# S32R372 register map
Vendor: Freescale Semiconductor, Inc.; Series: Qorivva; File version: 1.6
Registers are 32-bit, read-write, reset 0x0 unless marked. A register's access mark holds for its fields unless they carry their own. Offsets are from the block's base; [hi:lo] are bit positions; {n}, {i} and the like mark numbered series; 'fields as' and 'values as' point back to an identical list.

## SPT — Signal Processing Toolbox
Base 0xFFD10000; register names take the prefix SPT_
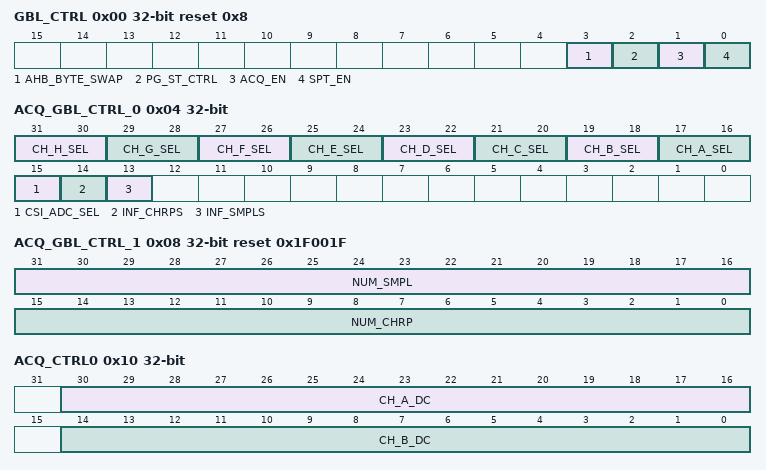
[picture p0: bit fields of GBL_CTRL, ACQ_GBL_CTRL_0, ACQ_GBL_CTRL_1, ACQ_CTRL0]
0x00 GBL_CTRL reset 0x8 — SPT Global Control Register
  [3] AHB_BYTE_SWAP — Bit to control data byte swapping on the AHB interface.
  [2] PG_ST_CTRL — Program start control
  [1] ACQ_EN — Acquisition Enable.
    0=Acquisition module is disabled. Acquisition and SDMA registers can now be programmed.; 1=Acquisition module is enabled. ADC samples can now be collected by acquisition block which are processed and transferred to System RAM by SDMA via AHB bus.
  [0] SPT_EN — SPT Enable
    0=SPT is disabled; 1=SPT is enabled
0x04 ACQ_GBL_CTRL_0 — Acquisition Global Control Register
  [31:30] CH_H_SEL — Channel H Select
    0=Channel Disabled; 1=Enable Channel H
  [29:28] CH_G_SEL — Channel G Select
    0=Channel Disabled; 1=Enable Channel G
  [27:26] CH_F_SEL — Channel F Select
    0=Channel Disabled; 1=Enable Channel F
  [25:24] CH_E_SEL — Channel E Select
    0=Channel Disabled; 1=Enable Channel E
  [23:22] CH_D_SEL — Channel D Select
    0=Channel Disabled; 1=Enable Channel D
  [21:20] CH_C_SEL — Channel C Select
    0=Channel Disabled; 1=Enable Channel C
  [19:18] CH_B_SEL — Channel B Select
    0=Channel Disabled; 1=Enable Channel B
  [17:16] CH_A_SEL — Channel A Select
    0=Channel Disabled; 1=Enable Channel A
  [15] CSI_ADC_SEL — CSI Select
    0=Acquisition source is disabled; 1=acquisition source is MIPICSI2 data
  [14] INF_CHRPS — Infinite Chirps in a Frame
    0=The number of chirps within a frame is limited and is programmable via ACQ_GBL_CTRL_1[NUM_CHRP] field; 1=The number of chirps within a frame is unlimited
  [13] INF_SMPLS — Infinite Samples in a Chirp
    0=The number of samples within a chirp is limited and is programmable via ACQ_GBL_CTRL_1[NUM_SMPL] field; 1=The number of samples within a chirp is unlimited
0x08 ACQ_GBL_CTRL_1 reset 0x1F001F — Acquisition Global Control Register 1
  [31:16] NUM_SMPL — Number of Samples in a Chirp
  [15:0] NUM_CHRP — Number of chirps in a frame
0x10 ACQ_CTRL0 — Acquisition Control 0 Register
  [30:16] CH_A_DC — Channel A Offset Compensation value
  [14:0] CH_B_DC — Channel B Offset Compensation value
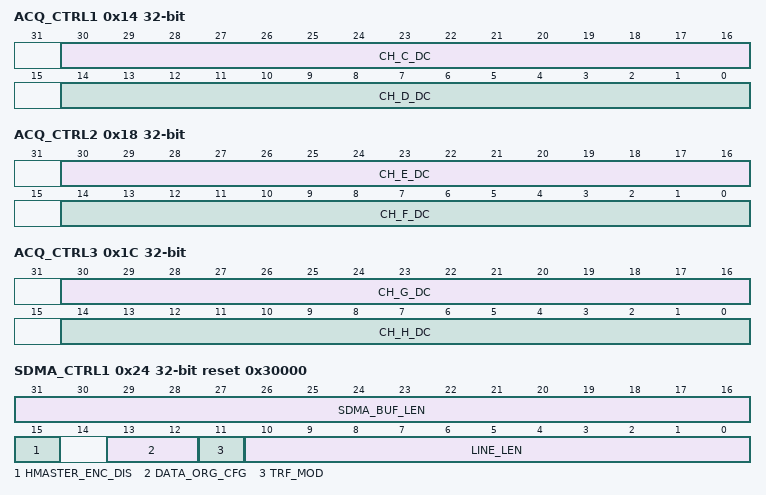
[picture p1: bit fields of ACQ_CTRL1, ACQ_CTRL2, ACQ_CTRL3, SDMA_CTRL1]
0x14 ACQ_CTRL1 — Acquisition Control 1 Register
  [30:16] CH_C_DC — Channel C Offset Compensation value
  [14:0] CH_D_DC — Channel D Offset Compensation value
0x18 ACQ_CTRL2 — Acquisition Control 2 Register
  [30:16] CH_E_DC — Channel E Offset Compensation value
  [14:0] CH_F_DC — Channel F Offset Compensation value
0x1C ACQ_CTRL3 — Acquisition Control 3 Register
  [30:16] CH_G_DC — Channel G Offset Compensation value
  [14:0] CH_H_DC — Channel H Offset Compensation value
0x20 SDMA_CTRL0 — SDMA Control 0 Register
  [31:3] SDMA_START_ADDR — SDMA Start Address
0x24 SDMA_CTRL1 reset 0x30000 — SDMA Control 1 Register
  [31:16] SDMA_BUF_LEN — SDMA Buffer Length
  [15] HMASTER_ENC_DIS — AHB Master ID generation disable
    0=Duplicate AHB Master ID generated. In this case the Duplicate AHB Master ID at the top shows a value different from the Crossbar Master ID; 1=Duplicate AHB Master ID not generated. In this case the Duplicate AHB Master ID at the top shows the same value as the Crossbar Master ID
  [13:12] DATA_ORG_CFG — Data Organization Configuration
    0=Interleaved Mode; 1=Tile 4 Mode; 2=Tile 8 Mode
  [11] TRF_MOD — Transfer Mode
    0=Selects Linear (1D) Mode; 1=Selects Orthogonal (2D) Mode
  [10:0] LINE_LEN — Line Length
0x44 ACQ_STATUS_A0 ro — Acquisition Status Register A0
  [31:0] CH_A_SUM — Channel A Sum
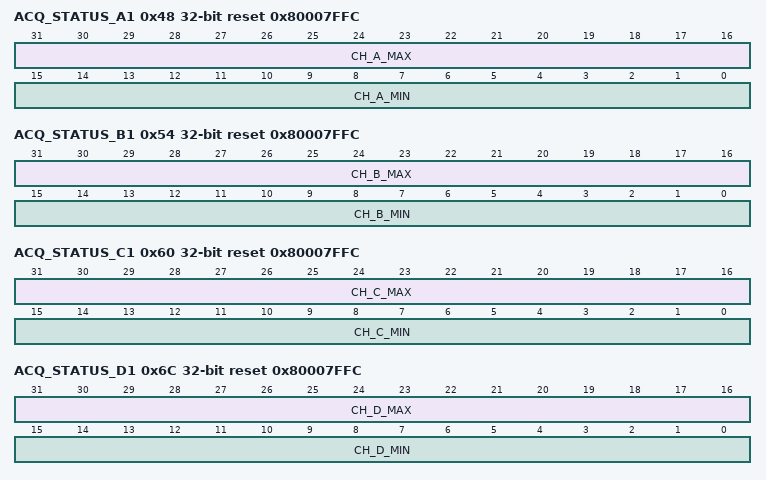
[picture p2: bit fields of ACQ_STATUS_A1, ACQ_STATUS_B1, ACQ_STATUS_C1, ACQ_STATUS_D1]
0x48 ACQ_STATUS_A1 ro reset 0x80007FFC — Acquisition Status Register A1
  [31:16] CH_A_MAX — Channel A Maximum
  [15:0] CH_A_MIN — Channel A Minimum
0x4C ACQ_STATUS_A2 ro — Acquisition Status Register A2
  [15:0] CH_A_BT — Channel A Bit Toggle
    0=The corresponding bit did not toggle; 1=The corresponding bit has toggled
0x50 ACQ_STATUS_B0 ro — Acquisition Status Register B0
  [31:0] CH_B_SUM — Channel B Sum
0x54 ACQ_STATUS_B1 ro reset 0x80007FFC — Acquisition Status Register B1
  [31:16] CH_B_MAX — Channel B Maximum
  [15:0] CH_B_MIN — Channel B Minimum
0x58 ACQ_STATUS_B2 ro — Acquisition Status Register B2
  [15:0] CH_B_BT — Channel B Bit Toggle
    values as ACQ_STATUS_A2.CH_A_BT
0x5C ACQ_STATUS_C0 ro — Acquisition Status Register C0
  [31:0] CH_C_SUM — Channel C Sum
0x60 ACQ_STATUS_C1 ro reset 0x80007FFC — Acquisition Status Register C1
  [31:16] CH_C_MAX — Channel C Maximum
  [15:0] CH_C_MIN — Channel C Minimum
0x64 ACQ_STATUS_C2 ro — Acquisition Status Register C2
  [15:0] CH_C_BT — Channel C Bit Toggle
    values as ACQ_STATUS_A2.CH_A_BT
0x68 ACQ_STATUS_D0 ro — Acquisition Status Register D0
  [31:0] CH_D_SUM — Channel D Sum
0x6C ACQ_STATUS_D1 ro reset 0x80007FFC — Acquisition Status Register D1
  [31:16] CH_D_MAX — Channel D Maximum
  [15:0] CH_D_MIN — Channel D Minimum
0x70 ACQ_STATUS_D2 ro — Acquisition Status Register D2
  [15:0] CH_D_BT — Channel D Bit Toggle
    values as ACQ_STATUS_A2.CH_A_BT
0x74 ACQ_STATUS_E0 ro — Acquisition Status Register E0
  [31:0] CH_E_SUM — Channel E Sum
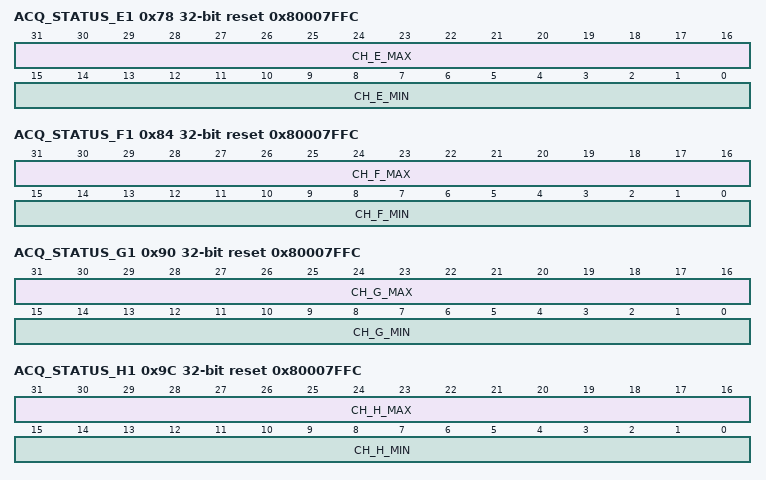
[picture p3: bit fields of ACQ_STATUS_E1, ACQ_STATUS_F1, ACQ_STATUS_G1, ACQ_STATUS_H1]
0x78 ACQ_STATUS_E1 ro reset 0x80007FFC — Acquisition Status Register E1
  [31:16] CH_E_MAX — Channel E Maximum
  [15:0] CH_E_MIN — Channel E Minimum
0x7C ACQ_STATUS_E2 ro — Acquisition Status Register E2
  [15:0] CH_E_BT — Channel E Bit Toggle
    values as ACQ_STATUS_A2.CH_A_BT
0x80 ACQ_STATUS_F0 ro — Acquisition Status Register F0
  [31:0] CH_F_SUM — Channel F Sum
0x84 ACQ_STATUS_F1 ro reset 0x80007FFC — Acquisition Status Register F1
  [31:16] CH_F_MAX — Channel F Maximum
  [15:0] CH_F_MIN — Channel F Minimum
0x88 ACQ_STATUS_F2 ro — Acquisition Status Register F2
  [15:0] CH_F_BT — Channel F Bit Toggle
    values as ACQ_STATUS_A2.CH_A_BT
0x8C ACQ_STATUS_G0 ro — Acquisition Status Register G0
  [31:0] CH_G_SUM — Channel G Sum
0x90 ACQ_STATUS_G1 ro reset 0x80007FFC — Acquisition Status Register G1
  [31:16] CH_G_MAX — Channel G Maximum
  [15:0] CH_G_MIN — Channel G Minimum
0x94 ACQ_STATUS_G2 ro — Acquisition Status Register G2
  [15:0] CH_G_BT — Channel G Bit Toggle
    values as ACQ_STATUS_A2.CH_A_BT
0x98 ACQ_STATUS_H0 ro — Acquisition Status Register H0
  [31:0] CH_H_SUM — Channel H Sum
0x9C ACQ_STATUS_H1 ro reset 0x80007FFC — Acquisition Status Register H1
  [31:16] CH_H_MAX — Channel H Maximum
  [15:0] CH_H_MIN — Channel H Minimum
0xA0 ACQ_STATUS_H2 ro — Acquisition Status Register H2
  [15:0] CH_H_BT — Channel H Bit Toggle
    values as ACQ_STATUS_A2.CH_A_BT
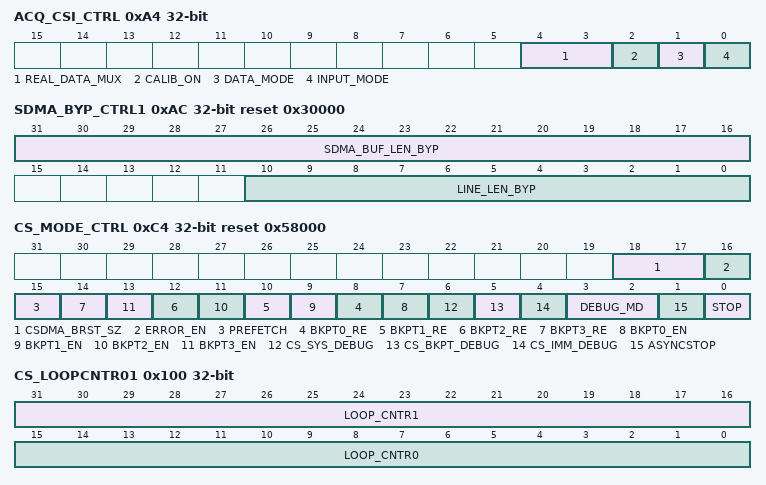
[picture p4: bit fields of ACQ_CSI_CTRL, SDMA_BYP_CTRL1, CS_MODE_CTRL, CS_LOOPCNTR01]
0xA4 ACQ_CSI_CTRL — Acquisition MIPICSI2 control register
  [4:3] REAL_DATA_MUX — Configures the sequence of data when channel 5 is on
    0=Channel A-D at 10MSPS and channel E at 10MSPS. RAW14 does not support this mode.; 1=Channel A-D at 5MSPS and channel E at 10MSPS; 2=Channel A-D at 2.5MSPS and channel E at 10MSPS; 3=Channel A-D at 6.667MSPS and channel E at 13.33MSPS
  [2] CALIB_ON — Enables the fifth channel
    0=calibration channel off; 1=calibration channel on
  [1] DATA_MODE — Defines the type of data.
    0=Input data is Real only; 1=Input data is complex (Real and Imaginary)
  [0] INPUT_MODE — Input Mode select
    0=Input data is in Tile4 format. Each channel receives 4 consecutive valid data.; 1=Input data in Interleaved format. Each channel receives 1 valid data at a time.
0xA8 SDMA_BYP_CTRL0 — Bypass SDMA Control 0
  [31:3] SDMA_START_ADDR_BYP — Bypass SDMA Start Address
0xAC SDMA_BYP_CTRL1 reset 0x30000 — Bypass SDMA Control 1 Register
  [31:16] SDMA_BUF_LEN_BYP — Bypass SDMA Buffer Length
  [10:0] LINE_LEN_BYP — Line Length Bypass
0xB0 ACQ_BYP_CTRL reset 0x1F0000 — Acquisition Bypass Control Register
  [31:16] NUM_SMPL_BYP — Number of Samples in a Chirp
0xC0 CS_PG_ST_ADDR — Program Start Addr Register
  [31:0] PG_ST_ADDR — Program start address
0xC4 CS_MODE_CTRL reset 0x58000 — Mode Control Register
  [18:17] CSDMA_BRST_SZ — Command Sequencer DMA Burst Size
    0=The burst size is INCR4; 1=The burst size is INCR8; 0b1x=The burst size is INCR16
  [16] ERROR_EN — Error Enable
  [15] PREFETCH — Early Pre-fetch Enable
    0=Early pre-fetch option disabled; 1=Early pre-fetch option enabled
  [2n+8] BKPT{n}_RE (n=0..3) — Breakpoint {n} remains enabled
  [2n+7] BKPT{n}_EN (n=0..3) — Breakpoint {n} enabled
  [6] CS_SYS_DEBUG — System debug enable
  [5] CS_BKPT_DEBUG — Breakpoint debug enable
  [4] CS_IMM_DEBUG — IMM DEBUG enable
  [3:2] DEBUG_MD — DEBUG MODE control
  [1] ASYNCSTOP wo — Asynchronous STOP bit
  [0] STOP wo — STOP bit
0xC8 CS_WD_COUNT ro — Watchdog Counter Register
  [23:0] WD_COUNT — Watchdog timer count
{0xCC+4i} CS_BKPT{i}_ADDR (i=0..3) — Breakpoint{i} Addr Register
  [31:0] BKPT{i} — Breakpoint {i} address
0xDC CS_JAM_INST0 — Jamming Instruction0 Register
  [31:0] JAM_INST_127_96 — Jamming instruction bits 127:96
0xE0 CS_JAM_INST1 — Jamming Instruction1 Register
  [31:0] JAM_INST_95_64 — Jamming instruction bits 95:64
0xE4 CS_JAM_INST2 — Jamming Instruction2 Register
  [31:0] JAM_INST_63_32 — Jamming instruction bits 63:32
0xE8 CS_JAM_INST3 — Jamming Instruction3 Register
  [31:0] JAM_INST_31_0 — Jamming instruction bits 31:0
0xEC CS_CURR_INST_ADDR ro — Current Instruction Addr Register
  [31:0] CURRENT_INST_ADDR — Current instruction pointer
0xF0 CS_CURR_INST0 ro — Current Instruction0 Register
  [31:0] CURR_INST_127_96 — Current instruction bits 127:96
0xF4 CS_CURR_INST1 ro — Current Instruction1 Register
  [31:0] CURR_INST_95_64 — Current instruction bits 95:64
0xF8 CS_CURR_INST2 ro — Current Instruction2 Register
  [31:0] CURR_INST_63_32 — Current instruction bits 63:32
0xFC CS_CURR_INST3 ro — Current Instruction3 Register
  [31:0] CURR_INST_31_0 — Current instruction bits 31:0
0x100 CS_LOOPCNTR01 ro — Loop Counter 0 and 1 Register
  [31:16] LOOP_CNTR1 — Loop count of counter 1
  [15:0] LOOP_CNTR0 — Loop count of counter 0
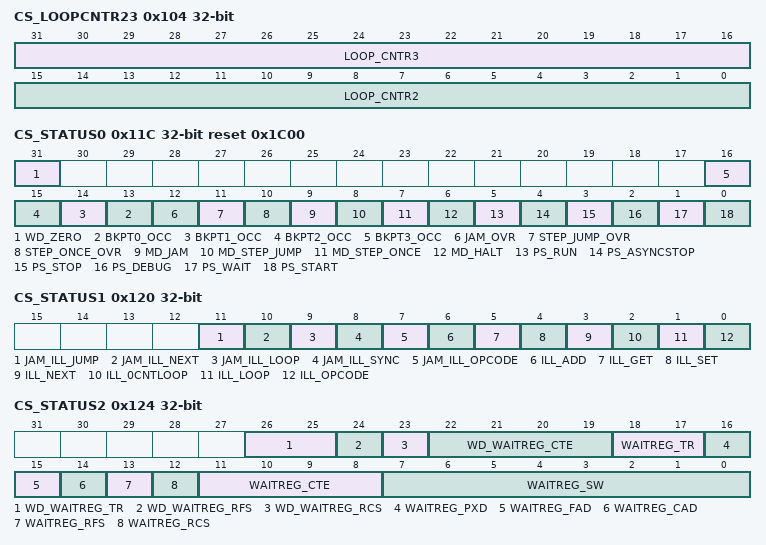
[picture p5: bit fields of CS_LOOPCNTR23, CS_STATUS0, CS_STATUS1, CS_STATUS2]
0x104 CS_LOOPCNTR23 ro — Loop Counter 2 and 3 Register
  [31:16] LOOP_CNTR3 — Loop count of counter 3
  [15:0] LOOP_CNTR2 — Loop count of counter 2
0x108 CS_ERR_INST_ADDR ro — Error Instruction Addr Register
  [31:0] ERROR_INST_ADDR — Error instruction pointer
0x10C CS_ERR_INST0 ro — Error Instruction 0 Register
  [31:0] ERR_INST_127_96 — Error instruction bits 127:96
0x110 CS_ERR_INST1 ro — Error Instruction 1 Register
  [31:0] ERR_INST_95_64 — Error instruction bits 95:64
0x114 CS_ERR_INST2 ro — Error Instruction 2 Register
  [31:0] ERR_INST_63_32 — Error instruction bits 63:32
0x118 CS_ERR_INST3 ro — Error Instruction 3 Register
  [31:0] ERR_INST_31_0 — Error instruction bits 31:0
0x11C CS_STATUS0 reset 0x1C00 — General Status 0 Register
  [31] WD_ZERO — Watchdog timer reached zero
  [n+13] BKPT{n}_OCC (n=0..3) — 'Breakpoint {n} hit' indication
  [12] JAM_OVR — Jamming mode instruction completion indication
  [11] STEP_JUMP_OVR — STEP JUMP mode break indication
  [10] STEP_ONCE_OVR — STEP ONCE mode instruction completion indication
  [9] MD_JAM — INSTRUCTION JAMMING mode indicator
  [8] MD_STEP_JUMP — STEP JUMP mode indicator
  [7] MD_STEP_ONCE — STEP ONCE mode indicator
  [6] MD_HALT — HALT MODE indicator
  [5] PS_RUN — RUN state indicator
  [4] PS_ASYNCSTOP — ASYNCSTOP state indicator
  [3] PS_STOP — STOP state indicator
  [2] PS_DEBUG — DEBUG state indicator
  [1] PS_WAIT — WAIT state indicator
  [0] PS_START — START state indicator
0x120 CS_STATUS1 — General Status 1 Register
  [11] JAM_ILL_JUMP — Illegal JUMP in jamming mode
  [10] JAM_ILL_NEXT — Illegal NEXT in jamming mode
  [9] JAM_ILL_LOOP — Illegal LOOP in jamming mode
  [8] JAM_ILL_SYNC — Illegal SYNC in jamming mode
  [7] JAM_ILL_OPCODE — Illegal opcode in jamming mode
  [6] ILL_ADD — Illegal ADD
  [5] ILL_GET — Illegal GET
  [4] ILL_SET — Illegal SET
  [3] ILL_NEXT — Illegal NEXT
  [2] ILL_0CNTLOOP — Illegal loop count error
  [1] ILL_LOOP — illegal LOOP
  [0] ILL_OPCODE — Illegal opcode
0x124 CS_STATUS2 ro — General Status2 Register
  [26:25] WD_WAITREG_TR — Event trigger type for WATCHDOG timer
  [24] WD_WAITREG_RFS — Watchdog waits for cte_rfs or csi_vsync signal
  [23] WD_WAITREG_RCS — Watchdog waits for cte_rcs or csi_hsync signal
  [22:19] WD_WAITREG_CTE — Watchdog waits for CTE
  [18:17] WAITREG_TR — Event trigger type
  [16] WAITREG_PXD — WAIT status for 'pdma transfer done' signal
  [15] WAITREG_FAD — WAIT status for 'frame acquisition done' signal
  [14] WAITREG_CAD — WAIT status for 'chirp acquisition done' signal
  [13] WAITREG_RFS — WAIT status for cte_rfs
  [12] WAITREG_RCS — WAIT status for cte_rcs
  [11:8] WAITREG_CTE — WAIT status for CTE event
  [7:0] WAITREG_SW — WAIT status for SW-enforced event
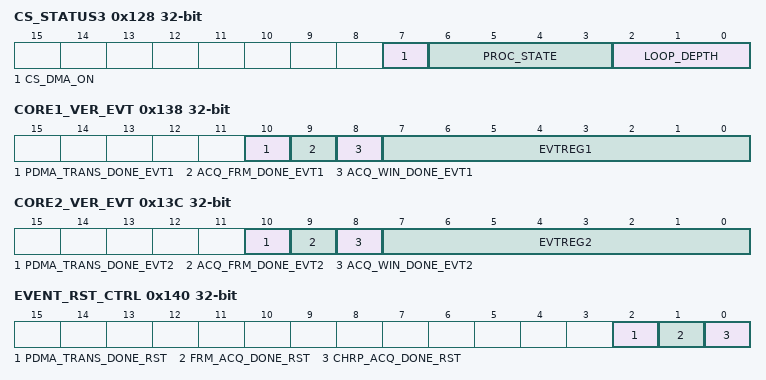
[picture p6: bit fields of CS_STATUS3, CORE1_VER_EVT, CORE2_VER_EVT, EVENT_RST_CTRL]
0x128 CS_STATUS3 ro — General Status 3 Register
  [7] CS_DMA_ON — Command sequencer DMA ON
  [6:3] PROC_STATE — Processing state
  [2:0] LOOP_DEPTH
0x12C CS_EVTREG1 — EVT1 Status Register
  [7:0] EVTREG1 — EVT1 register
0x130 CS_EVTREG2 — EVT2 Status Register
  [7:0] EVTREG2 — EVT2 register
0x134 CS_SW_EVTREG — SW Event Trigger Register
  [7:0] SW_EVTREG — SW event trigger
0x138 CORE1_VER_EVT — Core 1 Version Register Events
  [10] PDMA_TRANS_DONE_EVT1 — Event for PDMA transfer done for CPU core 1
  [9] ACQ_FRM_DONE_EVT1 — Event for acquisition frame done for CPU core 1
  [8] ACQ_WIN_DONE_EVT1 — Event for acquisition window finished for CPU core 1
  [7:0] EVTREG1 — EVT1 register
0x13C CORE2_VER_EVT — Core 2 Version Register Events
  [10] PDMA_TRANS_DONE_EVT2 — Event for PDMA transfer done for CPU core 2
  [9] ACQ_FRM_DONE_EVT2 — Event for acquisition frame done for CPU core 2
  [8] ACQ_WIN_DONE_EVT2 — Event for acquisition window finished for CPU core 2
  [7:0] EVTREG2 — EVT2 register
0x140 EVENT_RST_CTRL — SPT Event Reset Control Register
  [2] PDMA_TRANS_DONE_RST wo — When a 1 is written to this bit it causes the registered PDMA Transfer Done event inside the WAIT module to be reset
  [1] FRM_ACQ_DONE_RST wo — When a 1 is written to this bit it causes the registered Frame Acquisition Done event inside the WAIT module to be reset
  [0] CHRP_ACQ_DONE_RST wo — When a 1 is written to this bit it causes the registered Chirp Acquisition Done event inside the WAIT module to be reset
0x180 PDMA_LFSR_LOAD_VAL_HIGH — LFSR Load High Value
  [31:0] PDMA_LFSR_LOAD_VAL_HIGH — LFSR High value [63:32] for compression
0x184 PDMA_LFSR_LOAD_VAL_LOW — LFSR Load Low Value
  [31:0] PDMA_LFSR_LOAD_VAL_LOW — LFSR Low Value [31:0] for compression
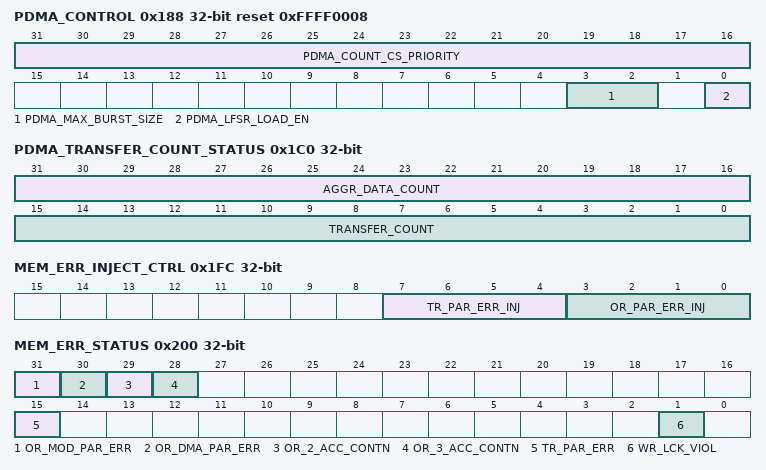
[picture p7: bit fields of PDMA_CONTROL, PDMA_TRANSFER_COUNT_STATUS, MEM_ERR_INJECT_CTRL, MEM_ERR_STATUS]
0x188 PDMA_CONTROL reset 0xFFFF0008
  [31:16] PDMA_COUNT_CS_PRIORITY — PDMA Count register for Command sequencer to get priority
  [3:2] PDMA_MAX_BURST_SIZE — Maximum AHB burst size
  [0] PDMA_LFSR_LOAD_EN — LFSR load enable bit
0x1C0 PDMA_TRANSFER_COUNT_STATUS ro
  [31:16] AGGR_DATA_COUNT — Aggregation Data Count
  [15:0] TRANSFER_COUNT — Number of words transferred via PDMA
0x1C4 PDMA_FMTB_EXP_ADDR_STATUS ro — PDMA formatB Exponent Address status Register
  [31:0] EXPN_ADDR — Exponent Address
0x1FC MEM_ERR_INJECT_CTRL — Memory Error Injection Register
  [7:4] TR_PAR_ERR_INJ — Twiddle RAM parity error Injection
  [3:0] OR_PAR_ERR_INJ — Operand RAM parity error Injection
0x200 MEM_ERR_STATUS — Memory Error Status Register
  [31] OR_MOD_PAR_ERR — Operand RAM module parity error
  [30] OR_DMA_PAR_ERR — Operand RAM DMA parity error
  [29] OR_2_ACC_CONTN — Operand RAM two access contention
  [28] OR_3_ACC_CONTN — Operand RAM three access contention
  [15] TR_PAR_ERR — Twiddle RAM parity error
  [1] WR_LCK_VIOL — Work register lock violation
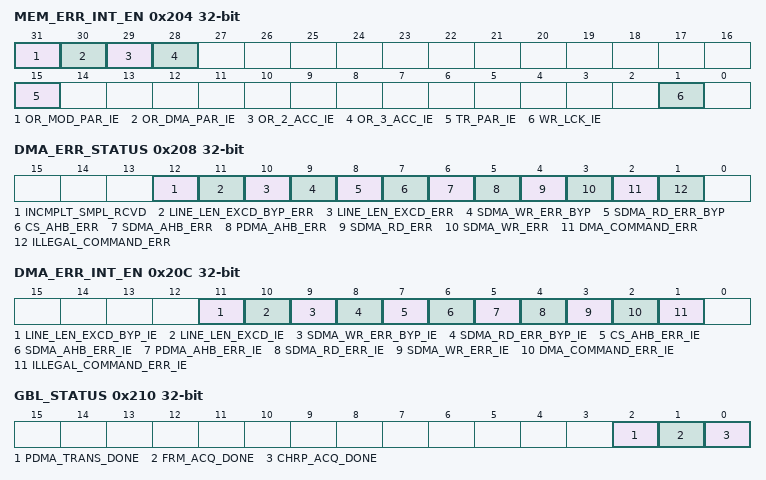
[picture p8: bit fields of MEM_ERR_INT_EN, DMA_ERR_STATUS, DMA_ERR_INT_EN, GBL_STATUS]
0x204 MEM_ERR_INT_EN — Memory Interrupt Enable register
  [31] OR_MOD_PAR_IE — Operand RAM module parity interrupt enable
  [30] OR_DMA_PAR_IE — Operand RAM DMA parity interrupt enable
  [29] OR_2_ACC_IE — Operand RAM two access contention interrupt enable
  [28] OR_3_ACC_IE — Operand RAM three access contention interrupt enable
  [15] TR_PAR_IE — Twiddle RAM parity error interrupt enable
  [1] WR_LCK_IE — Work register lock interrupt enable
0x208 DMA_ERR_STATUS — DMA Error Status Register
  [12] INCMPLT_SMPL_RCVD — Incomplete sample received
  [11] LINE_LEN_EXCD_BYP_ERR — Bypass SDMA line length exceeded
  [10] LINE_LEN_EXCD_ERR — Line Length Exceeded
  [9] SDMA_WR_ERR_BYP — Bypass SDMA write error
  [8] SDMA_RD_ERR_BYP — Bypass SDMA read error
  [7] CS_AHB_ERR — Command Sequencer AHB error Response
  [6] SDMA_AHB_ERR — SDMA AHB Error Response
  [5] PDMA_AHB_ERR — PDMA AHB Error
  [4] SDMA_RD_ERR — SDMA Read Error
  [3] SDMA_WR_ERR — SDMA Write Error
  [2] DMA_COMMAND_ERR — Generated if the transfer size is more than the maximum value possible
  [1] ILLEGAL_COMMAND_ERR — Generated if proprietary functionality is tried being used by user.
0x20C DMA_ERR_INT_EN — Interrupt Enable for DMA_ERROR_STATUS
  [11] LINE_LEN_EXCD_BYP_IE — Bypass SDMA line length exceeded interrupt
    0=Interrupt generation disabled; 1=Interrupt generation enabled
  [10] LINE_LEN_EXCD_IE — Line length exceeded interrupt
    values as LINE_LEN_EXCD_BYP_IE
  [9] SDMA_WR_ERR_BYP_IE — Bypass SDMA write error interrupt
    values as LINE_LEN_EXCD_BYP_IE
  [8] SDMA_RD_ERR_BYP_IE — Bypass SDMA read error interrupt
    values as LINE_LEN_EXCD_BYP_IE
  [7] CS_AHB_ERR_IE — Command Sequencer AHB Interrupt Enable
  [6] SDMA_AHB_ERR_IE — SDMA AHB Error Interrupt Enable
  [5] PDMA_AHB_ERR_IE — Interrupt Enable for PDMA AHB Error
  [4] SDMA_RD_ERR_IE — SDMA Read Error Interrupt Enable
    values as LINE_LEN_EXCD_BYP_IE
  [3] SDMA_WR_ERR_IE — SDMA Write Error Interrupt Enable
    values as LINE_LEN_EXCD_BYP_IE
  [2] DMA_COMMAND_ERR_IE — Generated if the transfer size is more than the maximum value possible
  [1] ILLEGAL_COMMAND_ERR_IE — Generated if proprietary functionality is tried being used by user.
0x210 GBL_STATUS — Global Status Register
  [2] PDMA_TRANS_DONE — PDMA transfer done
  [1] FRM_ACQ_DONE — Frame Acquisition Done
    0=Frame Acquisition is not done; 1=Frame Acquisition is done
  [0] CHRP_ACQ_DONE — Chirp Acquisition Done
    0=Chirp Acquisition is not done; 1=Chirp acquisition is done
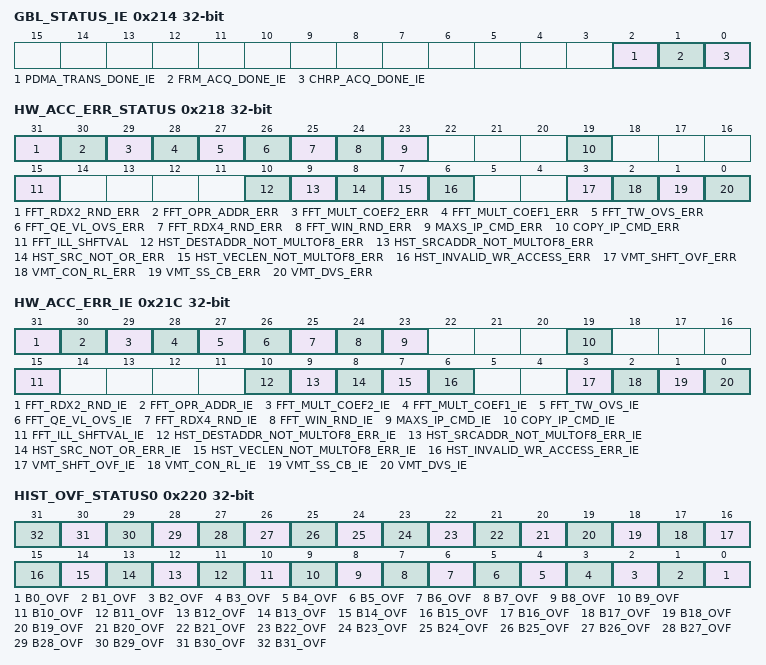
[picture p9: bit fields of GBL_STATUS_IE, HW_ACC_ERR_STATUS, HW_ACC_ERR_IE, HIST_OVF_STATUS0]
0x214 GBL_STATUS_IE — Global Status Interrupt Enable Register
  [2] PDMA_TRANS_DONE_IE — PDMA transfer done interrupt enable
  [1] FRM_ACQ_DONE_IE — Frame Acquisition Done Interrupt Enable
    0=Interrupt Disabled; 1=Interrupt Enabled
  [0] CHRP_ACQ_DONE_IE — Chirp Acquisition Done Interrupt Enable
    0=Interrupt Disabled; 1=Interrupt Enabled
0x218 HW_ACC_ERR_STATUS — Hardware Accelerator Error Status Register
  [31] FFT_RDX2_RND_ERR — FFT Radix2 Round Error
  [30] FFT_OPR_ADDR_ERR — Operand Address Error
  [29] FFT_MULT_COEF2_ERR — FFT MULT Co-efficient 2 Error
  [28] FFT_MULT_COEF1_ERR — FFT MULT Co-efficient 1 Error
  [27] FFT_TW_OVS_ERR — FFT Twiddle Oversampling Error
  [26] FFT_QE_VL_OVS_ERR — Quadrature Extension Vector Length Oversampling Error
  [25] FFT_RDX4_RND_ERR — FFT Radix4 Round Error
  [24] FFT_WIN_RND_ERR — FFT Window Round Error
  [23] MAXS_IP_CMD_ERR — MAXS input command error
    0=No command error; 1=Asserted when any of the following errors are encountered in the incoming instruction. Refer Error scenarios
  [19] COPY_IP_CMD_ERR — COPY input command error
    0=No command error; 1=Asserted when any of the following command errors are encountered: 1.In in_dattyp = CMPLX and preproc = 0 (no preproc) 2.If in_dattyp != CMPLX and preproc = 2 (MAG) 3.If (src_add[15:14] = WREG_ADD or dest_add[15:14] = WREG_ADD) 4.In_dattyp == 11b (RESERVED) 5.Preproc == 11b (RESERVED) 6.Cp_type >= 1100b 7.Cp_type == CP_TRNSPOSE and vec_sz[5:0] != 0 8.Vec_sz[3:0] != 0 9.Cp_type == CP_SHFT AND dest_add[3:0] == 0 // copy shift with 0 shift not allowed
  [15] FFT_ILL_SHFTVAL — FFT Illegal Shift Value error
  [10] HST_DESTADDR_NOT_MULTOF8_ERR — Destination address not multiple of 8 error
  [9] HST_SRCADDR_NOT_MULTOF8_ERR — Source address not multiple of 8 error
  [8] HST_SRC_NOT_OR_ERR — Source not Operand RAM error
  [7] HST_VECLEN_NOT_MULTOF8_ERR — Vector length not multiple of 8 error
  [6] HST_INVALID_WR_ACCESS_ERR — HIST work register access error
  [3] VMT_SHFT_OVF_ERR — VMT Shift Overflow Error
    0=No saturation condition hit; 1=Saturation condition is hit
  [2] VMT_CON_RL_ERR — VMT Conjugate with Real Type Error
    0=No Error; 1=Error condition is hit
  [1] VMT_SS_CB_ERR — VMT Sum Scale with Conjugate/Bypass Error
    0=No Error; 1=Error condition is hit
  [0] VMT_DVS_ERR — VMT Dual vector sum error
    0=No Error; 1=Error condition is hit
0x21C HW_ACC_ERR_IE — Hardware Accelerator Error Interrupt Enable Register
  [31] FFT_RDX2_RND_IE — FFT Radix2 Round Error Interrupt Enable
  [30] FFT_OPR_ADDR_IE — Operand Address Interrupt Enable
    0=Interrupt Disabled; 1=Interrupt Enabled
  [29] FFT_MULT_COEF2_IE — FFT MULT Co-efficient 2 Interrupt Enable
    0=Interrupt Disabled; 1=Interrupt Enabled
  [28] FFT_MULT_COEF1_IE — FFT MULT Co-efficient 1 Interrupt Enable
    0=Interrupt Disabled; 1=Interrupt Enabled
  [27] FFT_TW_OVS_IE — FFT Twiddle Oversampling Interrupt Enable
    0=Interrupt Disabled; 1=Interrupt Enabled
  [26] FFT_QE_VL_OVS_IE — Quadrature Extension Vector Length Oversampling Interrupt Enable
    0=Interrupt Disabled; 1=Interrupt Enabled
  [25] FFT_RDX4_RND_IE — FFT Radix4 Round Error Interrupt Enable
  [24] FFT_WIN_RND_IE — FFT Window Round Interrupt Enable
    0=Interrupt Disabled; 1=Interrupt Enabled
  [23] MAXS_IP_CMD_IE — MAXS input command interrupt enable
  [19] COPY_IP_CMD_IE — COPY input command interrupt enable
  [15] FFT_ILL_SHFTVAL_IE — FFT Illegal Shift Value Error
  [10] HST_DESTADDR_NOT_MULTOF8_ERR_IE — Destination address not multiple of 8 error interrupt enable
  [9] HST_SRCADDR_NOT_MULTOF8_ERR_IE — Source address not multiple of 8 error interrupt enable
  [8] HST_SRC_NOT_OR_ERR_IE — Source not Operand RAM error interrupt enable
  [7] HST_VECLEN_NOT_MULTOF8_ERR_IE — Vector length not multiple of 8 error interrupt enable
  [6] HST_INVALID_WR_ACCESS_ERR_IE — HIST work register access error interrupt enable
  [3] VMT_SHFT_OVF_IE — VMT Shift Overflow Interrupt Enable.
    0=Interrupt Disabled; 1=Interrupt Enabled
  [2] VMT_CON_RL_IE — VMT Conjugate with Real Type Interrupt Enable
    0=Interrupt Disabled; 1=Interrupt Enabled
  [1] VMT_SS_CB_IE — VMT Sum Scale with Conjugate/Bypass Interrupt Enable
    0=Interrupt Disabled; 1=Interrupt Enabled
  [0] VMT_DVS_IE — VMT Dual vector sum Interrupt Enable
    0=Interrupt Disabled; 1=Interrupt Enabled
0x220 HIST_OVF_STATUS0 — HIST Overflow Status0 Register
  [n] B{n}_OVF (n=0..31) — Bin {n} overflow
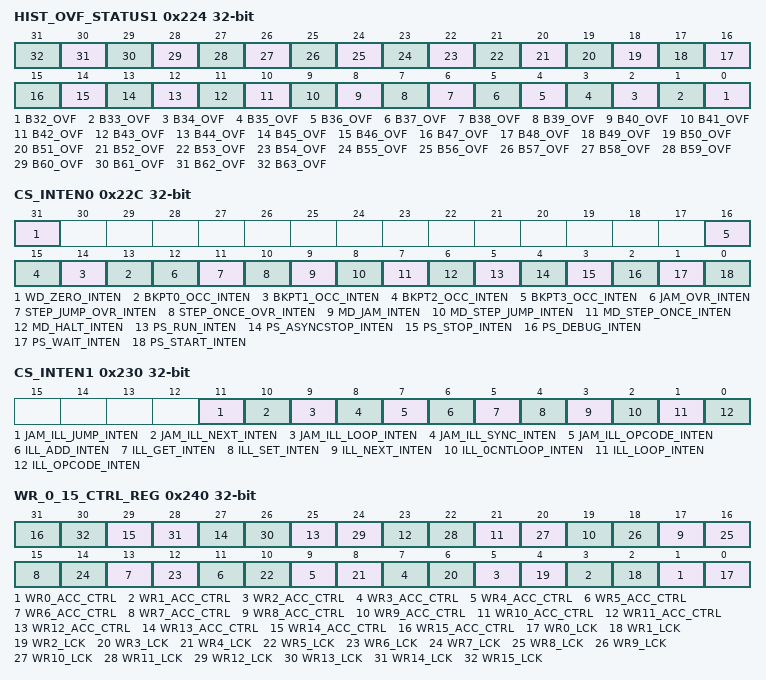
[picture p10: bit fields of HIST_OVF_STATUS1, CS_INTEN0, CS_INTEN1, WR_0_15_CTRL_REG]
0x224 HIST_OVF_STATUS1 — HIST Overflow Status1 Register
  [n-32] B{n}_OVF (n=32..63) — Bin {n} overflow
0x228 HIST_OVF_IE — HIST Overflow Interrupt Enable Register
  [0] OVF_IE — HIST overflow interrupt enable
0x22C CS_INTEN0 — Interrupt Enable Register 0
  [31] WD_ZERO_INTEN — Watchdog reached zero interrupt enable
  [n+13] BKPT{n}_OCC_INTEN (n=0..3) — BKPT{n} interrupt enable
  [12] JAM_OVR_INTEN — Jamming instruction over interrupt enable
  [11] STEP_JUMP_OVR_INTEN — 'Breakpoint hit in STEP JUMP mode' interrupt enable
  [10] STEP_ONCE_OVR_INTEN — STEP ONCE mode instruction over interrupt enable
  [9] MD_JAM_INTEN — Interrupt enable for instruction jamming mode
  [8] MD_STEP_JUMP_INTEN — Interrupt enable for STEP JUMP mode
  [7] MD_STEP_ONCE_INTEN — Interrupt enable for STEP ONCE mode
  [6] MD_HALT_INTEN — Interrupt enable for HALT mode
  [5] PS_RUN_INTEN — Interrupt enable for RUN state
  [4] PS_ASYNCSTOP_INTEN — Interrupt enable for ASYNCSTOP state
  [3] PS_STOP_INTEN — Interrupt enable for STOP state
  [2] PS_DEBUG_INTEN — Interrupt enable for DEBUG state
  [1] PS_WAIT_INTEN — Interrupt enable for WAIT state
  [0] PS_START_INTEN — Interrupt enable for START state
0x230 CS_INTEN1 — Interrupt Enable Register 1
  [11] JAM_ILL_JUMP_INTEN — Illegal JUMP in jamming mode interrupt enable
  [10] JAM_ILL_NEXT_INTEN — Illegal NEXT in jamming mode interrupt enable
  [9] JAM_ILL_LOOP_INTEN — Illegal LOOP in jamming mode interrupt enable
  [8] JAM_ILL_SYNC_INTEN — Illegal SYNC in jamming mode interrupt enable
  [7] JAM_ILL_OPCODE_INTEN — Illegal Opcode in jamming mode interrupt enable
  [6] ILL_ADD_INTEN — Illegal ADD interrupt enable
  [5] ILL_GET_INTEN — Illegal GET interrupt enable
  [4] ILL_SET_INTEN — Illegal SET interrupt enable
  [3] ILL_NEXT_INTEN — Illegal NEXT interrupt enable
  [2] ILL_0CNTLOOP_INTEN — Illegal loop count error interrupt
  [1] ILL_LOOP_INTEN — Illegal LOOP interrupt enable
  [0] ILL_OPCODE_INTEN — Illegal Opcode interrupt enable
0x234 CS_EVT1_INTEN — EVT1 Interrupt Enable Register
  [7:0] EVT1_INTEN — EVT interrupt enable for CPU core 1
0x238 CS_EVT2_INTEN — EVT2 Interrupt Enable Register
  [7:0] EVT2_INTEN — EVT interrupt enable for CPU core 2
0x240 WR_0_15_CTRL_REG
  [2n+1] WR{n}_ACC_CTRL (n=0..15) — Work register {n} access control
  [2n] WR{n}_LCK (n=0..15) — Work register {n} lock
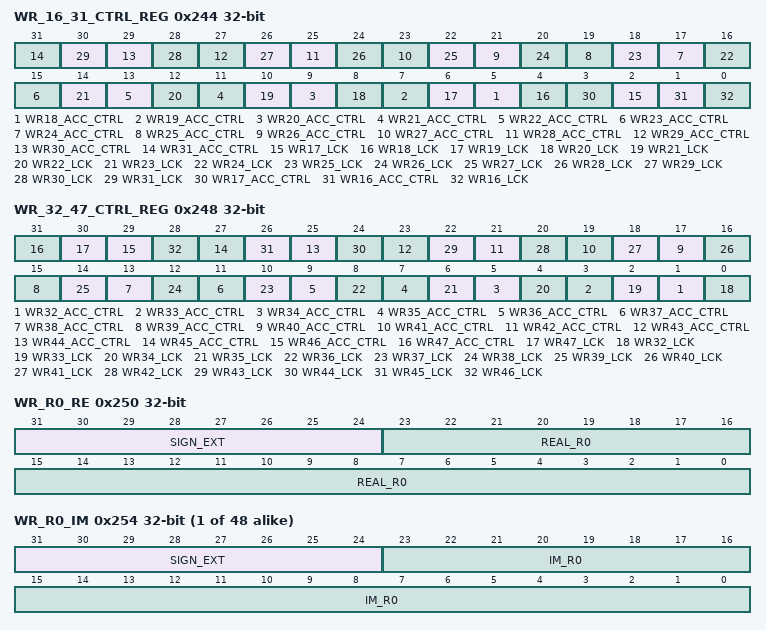
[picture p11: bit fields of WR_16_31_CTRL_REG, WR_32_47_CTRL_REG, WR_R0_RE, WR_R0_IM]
0x244 WR_16_31_CTRL_REG
  [2n-31] WR{n}_ACC_CTRL (n=18..31) — Work register {n} access control
  [2n-32] WR{n}_LCK (n=17..31) — Work register {n} lock
  [3] WR17_ACC_CTRL — Work register 1 access control
  [1] WR16_ACC_CTRL — Work register 15 access control
  [0] WR16_LCK — Work register 15 lock
0x248 WR_32_47_CTRL_REG
  [2n-63] WR{n}_ACC_CTRL (n=32..47) — Work register {n} access control
  [30] WR47_LCK — Work register 31 lock
  [2n-64] WR{n}_LCK (n=32..46) — Work register {n} lock
0x250 WR_R0_RE — Work Register R0 Real
  [31:24] SIGN_EXT ro — Sign Extension
  [23:0] REAL_R0 — Real part of Work Register R0
{0x254+8i} WR_R{i}_IM (i=0..47) — Work Register R{i} Imaginary
  [31:24] SIGN_EXT ro — Sign Extension
  [23:0] IM_R{i} — Imaginary part of Work Register R{i}
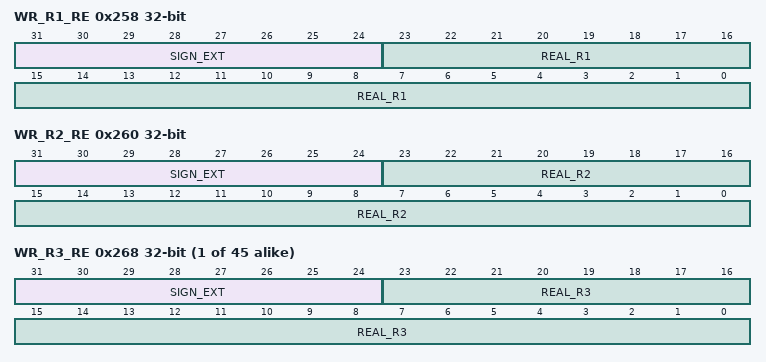
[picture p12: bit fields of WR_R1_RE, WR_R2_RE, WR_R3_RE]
0x258 WR_R1_RE — Work Register R1 Real
  [31:24] SIGN_EXT ro — Sign Extension
  [23:0] REAL_R1 — Real part of Work Register R1
0x260 WR_R2_RE — Work Register R0 Real
  [31:24] SIGN_EXT ro — Sign Extension
  [23:0] REAL_R2 — Real part of Work Register R2
{0x250+8i} WR_R{i}_RE (i=3..47) — Work Register R{i} Real
  [31:24] SIGN_EXT ro — Sign Extension
  [23:0] REAL_R{i} — Real part of Work Register R{i}
